AUTOSAR XML (schema 4-0-3)
package /CalibrationComponents
  parameter sw component type HMIR: data-type-mapping=HMIR_CodeDataTypeMappingsSet
    provide port HMIR_Pport: provided-interface=HMIR_if
      provided-com-specs:
        init-value=55, parameter=KeHMIR_Ah_BattRatedCap
        init-value=55, parameter=KeHMIR_Ah_CellCapacity
        init-value=18.299999237060547, parameter=KeHMIR_I_MaxChargeCur
        init-value=97, parameter=KeHMIR_Pct_PackSocDashHundred
        init-value=3, parameter=KeHMIR_Pct_PackSocDashZero
        init-value=350.3999938964844, parameter=KeHMIR_U_BattRatedVoltageValue
        init-value=2.799999952316284, parameter=KeHMIR_U_CellDischCutVoltage
        init-value=403.20001220703125, parameter=KeHMIR_U_MaxChargeVol
        init-value=268.79998779296875, parameter=KeHMIR_U_MinChargeVol
        init-value=19.299999237060547, parameter=KeHMIR_kE_BattRatedEnergyValue
        init-value=250, parameter=KeHMIR_kl_ElectricRangeDTE_Value
        init-value=100, parameter=KeHMIR_kl_TotalDrivenBatOvrdVal
        init-value=110105, parameter=KeHMIR_k_PRTVer
        init-value=0, parameter=KeHMIR_b_TotalDrivenBatOvrd
        init-value=6, parameter=KeHMIR_k_BattManucCodeVal
        init-value=1, parameter=KeHMIR_k_BattNum
        init-value=1, parameter=KeHMIR_k_BattPackParallel
        init-value=96, parameter=KeHMIR_k_BattPackSerial
        init-value=1, parameter=KeHMIR_k_BattSum
        init-value=4, parameter=KeHMIR_k_BattTypeValue
        init-value=96, parameter=KeHMIR_k_CellNum
        init-value=10, parameter=KeHMIR_k_CodeL
        init-value=29, parameter=KeHMIR_k_FaultSum
        init-value=2, parameter=KeHMIR_k_HWVer
        init-value=96, parameter=KeHMIR_k_MaxCellIndex
        init-value=1, parameter=KeHMIR_k_MaxTNumPack
        init-value=16, parameter=KeHMIR_k_MaxTempIndex
        init-value=1, parameter=KeHMIR_k_MaxVNumPack
        init-value=1, parameter=KeHMIR_k_MinCellIndex
        init-value=1, parameter=KeHMIR_k_MinTNumPack
        init-value=1, parameter=KeHMIR_k_MinTempIndex
        init-value=1, parameter=KeHMIR_k_MinVNumPack
        init-value=16, parameter=KeHMIR_k_TempNum
package /HMIR_Code_pkg/HMIR_Code_swc
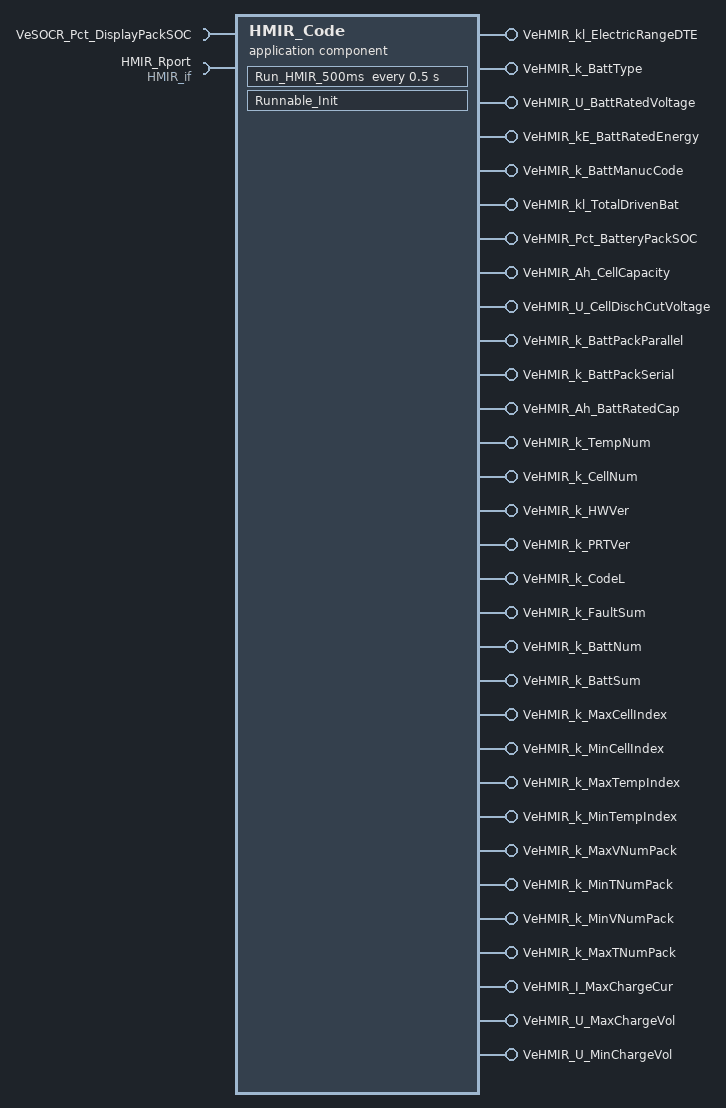
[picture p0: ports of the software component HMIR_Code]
  application sw component type HMIR_Code
    require port VeSOCR_Pct_DisplayPackSOC: nonqueued-receiver-com-spec{data-element=VeSOCR_Pct_DisplayPackSOC, init-value=0}, required-interface=VeSOCR_Pct_DisplayPackSOC
    31 x provide port:
      VeHMIR_kl_ElectricRangeDTE: nonqueued-sender-com-spec{data-element=VeHMIR_kl_ElectricRangeDTE, init-value=0}, provided-interface=VeHMIR_kl_ElectricRangeDTE
      VeHMIR_k_BattType: nonqueued-sender-com-spec{data-element=VeHMIR_k_BattType, init-value=0}, provided-interface=VeHMIR_k_BattType
      VeHMIR_U_BattRatedVoltage: nonqueued-sender-com-spec{data-element=VeHMIR_U_BattRatedVoltage, init-value=0}, provided-interface=VeHMIR_U_BattRatedVoltage
      VeHMIR_kE_BattRatedEnergy: nonqueued-sender-com-spec{data-element=VeHMIR_kE_BattRatedEnergy, init-value=0}, provided-interface=VeHMIR_kE_BattRatedEnergy
      VeHMIR_k_BattManucCode: nonqueued-sender-com-spec{data-element=VeHMIR_k_BattManucCode, init-value=0}, provided-interface=VeHMIR_k_BattManucCode
      VeHMIR_kl_TotalDrivenBat: nonqueued-sender-com-spec{data-element=VeHMIR_kl_TotalDrivenBat, init-value=0}, provided-interface=VeHMIR_kl_TotalDrivenBat
      VeHMIR_Pct_BatteryPackSOC: nonqueued-sender-com-spec{data-element=VeHMIR_Pct_BatteryPackSOC, init-value=0}, provided-interface=VeHMIR_Pct_BatteryPackSOC
      VeHMIR_Ah_CellCapacity: nonqueued-sender-com-spec{data-element=VeHMIR_Ah_CellCapacity, init-value=0}, provided-interface=VeHMIR_Ah_CellCapacity
      VeHMIR_U_CellDischCutVoltage: nonqueued-sender-com-spec{data-element=VeHMIR_U_CellDischCutVoltage, init-value=0}, provided-interface=VeHMIR_U_CellDischCutVoltage
      VeHMIR_k_BattPackParallel: nonqueued-sender-com-spec{data-element=VeHMIR_k_BattPackParallel, init-value=0}, provided-interface=VeHMIR_k_BattPackParallel
      VeHMIR_k_BattPackSerial: nonqueued-sender-com-spec{data-element=VeHMIR_k_BattPackSerial, init-value=0}, provided-interface=VeHMIR_k_BattPackSerial
      VeHMIR_Ah_BattRatedCap: nonqueued-sender-com-spec{data-element=VeHMIR_Ah_BattRatedCap, init-value=0}, provided-interface=VeHMIR_Ah_BattRatedCap
      VeHMIR_k_TempNum: nonqueued-sender-com-spec{data-element=VeHMIR_k_TempNum, init-value=0}, provided-interface=VeHMIR_k_TempNum
      VeHMIR_k_CellNum: nonqueued-sender-com-spec{data-element=VeHMIR_k_CellNum, init-value=0}, provided-interface=VeHMIR_k_CellNum
      VeHMIR_k_HWVer: nonqueued-sender-com-spec{data-element=VeHMIR_k_HWVer, init-value=0}, provided-interface=VeHMIR_k_HWVer
      VeHMIR_k_PRTVer: nonqueued-sender-com-spec{data-element=VeHMIR_k_PRTVer, init-value=0}, provided-interface=VeHMIR_k_PRTVer
      VeHMIR_k_CodeL: nonqueued-sender-com-spec{data-element=VeHMIR_k_CodeL, init-value=0}, provided-interface=VeHMIR_k_CodeL
      VeHMIR_k_FaultSum: nonqueued-sender-com-spec{data-element=VeHMIR_k_FaultSum, init-value=0}, provided-interface=VeHMIR_k_FaultSum
      VeHMIR_k_BattNum: nonqueued-sender-com-spec{data-element=VeHMIR_k_BattNum, init-value=0}, provided-interface=VeHMIR_k_BattNum
      VeHMIR_k_BattSum: nonqueued-sender-com-spec{data-element=VeHMIR_k_BattSum, init-value=0}, provided-interface=VeHMIR_k_BattSum
      VeHMIR_k_MaxCellIndex: nonqueued-sender-com-spec{data-element=VeHMIR_k_MaxCellIndex, init-value=0}, provided-interface=VeHMIR_k_MaxCellIndex
      VeHMIR_k_MinCellIndex: nonqueued-sender-com-spec{data-element=VeHMIR_k_MinCellIndex, init-value=0}, provided-interface=VeHMIR_k_MinCellIndex
      VeHMIR_k_MaxTempIndex: nonqueued-sender-com-spec{data-element=VeHMIR_k_MaxTempIndex, init-value=0}, provided-interface=VeHMIR_k_MaxTempIndex
      VeHMIR_k_MinTempIndex: nonqueued-sender-com-spec{data-element=VeHMIR_k_MinTempIndex, init-value=0}, provided-interface=VeHMIR_k_MinTempIndex
      VeHMIR_k_MaxVNumPack: nonqueued-sender-com-spec{data-element=VeHMIR_k_MaxVNumPack, init-value=0}, provided-interface=VeHMIR_k_MaxVNumPack
      VeHMIR_k_MinTNumPack: nonqueued-sender-com-spec{data-element=VeHMIR_k_MinTNumPack, init-value=0}, provided-interface=VeHMIR_k_MinTNumPack
      VeHMIR_k_MinVNumPack: nonqueued-sender-com-spec{data-element=VeHMIR_k_MinVNumPack, init-value=0}, provided-interface=VeHMIR_k_MinVNumPack
      VeHMIR_k_MaxTNumPack: nonqueued-sender-com-spec{data-element=VeHMIR_k_MaxTNumPack, init-value=0}, provided-interface=VeHMIR_k_MaxTNumPack
      VeHMIR_I_MaxChargeCur: nonqueued-sender-com-spec{data-element=VeHMIR_I_MaxChargeCur, init-value=0}, provided-interface=VeHMIR_I_MaxChargeCur
      VeHMIR_U_MaxChargeVol: nonqueued-sender-com-spec{data-element=VeHMIR_U_MaxChargeVol, init-value=0}, provided-interface=VeHMIR_U_MaxChargeVol
      VeHMIR_U_MinChargeVol: nonqueued-sender-com-spec{data-element=VeHMIR_U_MinChargeVol, init-value=0}, provided-interface=VeHMIR_U_MinChargeVol
    require port HMIR_Rport: required-interface=HMIR_if
    behavior HMIR_Code: constant-value-mapping=HMIR_Code_datatype_AVS_MappingSet, data-type-mapping=HMIR_CodeDataTypeMappingsSet, handle-termination-and-restart=NO-SUPPORT
      timing event Event_Run_HMIR_500ms: start-on-event=Run_HMIR_500ms, period=0.5
      runnable Runnable_Init: symbol=HMIR_Code_Init
        data-send-points:
          29 x access:
            OUT_VeHMIR_kl_ElectricRangeDTE_VeHMIR_kl_ElectricRangeDTE: accessed-variable=VeHMIR_kl_ElectricRangeDTE.VeHMIR_kl_ElectricRangeDTE
            OUT_VeHMIR_k_BattType_VeHMIR_k_BattType: accessed-variable=VeHMIR_k_BattType.VeHMIR_k_BattType
            OUT_VeHMIR_U_BattRatedVoltage_VeHMIR_U_BattRatedVoltage: accessed-variable=VeHMIR_U_BattRatedVoltage.VeHMIR_U_BattRatedVoltage
            OUT_VeHMIR_kE_BattRatedEnergy_VeHMIR_kE_BattRatedEnergy: accessed-variable=VeHMIR_kE_BattRatedEnergy.VeHMIR_kE_BattRatedEnergy
            OUT_VeHMIR_k_BattManucCode_VeHMIR_k_BattManucCode: accessed-variable=VeHMIR_k_BattManucCode.VeHMIR_k_BattManucCode
            OUT_VeHMIR_Ah_CellCapacity_VeHMIR_Ah_CellCapacity: accessed-variable=VeHMIR_Ah_CellCapacity.VeHMIR_Ah_CellCapacity
            OUT_VeHMIR_U_CellDischCutVoltage_VeHMIR_U_CellDischCutVoltage: accessed-variable=VeHMIR_U_CellDischCutVoltage.VeHMIR_U_CellDischCutVoltage
            OUT_VeHMIR_k_BattPackParallel_VeHMIR_k_BattPackParallel: accessed-variable=VeHMIR_k_BattPackParallel.VeHMIR_k_BattPackParallel
            OUT_VeHMIR_k_BattPackSerial_VeHMIR_k_BattPackSerial: accessed-variable=VeHMIR_k_BattPackSerial.VeHMIR_k_BattPackSerial
            OUT_VeHMIR_Ah_BattRatedCap_VeHMIR_Ah_BattRatedCap: accessed-variable=VeHMIR_Ah_BattRatedCap.VeHMIR_Ah_BattRatedCap
            OUT_VeHMIR_k_TempNum_VeHMIR_k_TempNum: accessed-variable=VeHMIR_k_TempNum.VeHMIR_k_TempNum
            OUT_VeHMIR_k_CellNum_VeHMIR_k_CellNum: accessed-variable=VeHMIR_k_CellNum.VeHMIR_k_CellNum
            OUT_VeHMIR_k_HWVer_VeHMIR_k_HWVer: accessed-variable=VeHMIR_k_HWVer.VeHMIR_k_HWVer
            OUT_VeHMIR_k_PRTVer_VeHMIR_k_PRTVer: accessed-variable=VeHMIR_k_PRTVer.VeHMIR_k_PRTVer
            OUT_VeHMIR_k_CodeL_VeHMIR_k_CodeL: accessed-variable=VeHMIR_k_CodeL.VeHMIR_k_CodeL
            OUT_VeHMIR_k_FaultSum_VeHMIR_k_FaultSum: accessed-variable=VeHMIR_k_FaultSum.VeHMIR_k_FaultSum
            OUT_VeHMIR_k_BattNum_VeHMIR_k_BattNum: accessed-variable=VeHMIR_k_BattNum.VeHMIR_k_BattNum
            OUT_VeHMIR_k_BattSum_VeHMIR_k_BattSum: accessed-variable=VeHMIR_k_BattSum.VeHMIR_k_BattSum
            OUT_VeHMIR_k_MaxCellIndex_VeHMIR_k_MaxCellIndex: accessed-variable=VeHMIR_k_MaxCellIndex.VeHMIR_k_MaxCellIndex
            OUT_VeHMIR_k_MinCellIndex_VeHMIR_k_MinCellIndex: accessed-variable=VeHMIR_k_MinCellIndex.VeHMIR_k_MinCellIndex
            OUT_VeHMIR_k_MaxTempIndex_VeHMIR_k_MaxTempIndex: accessed-variable=VeHMIR_k_MaxTempIndex.VeHMIR_k_MaxTempIndex
            OUT_VeHMIR_k_MinTempIndex_VeHMIR_k_MinTempIndex: accessed-variable=VeHMIR_k_MinTempIndex.VeHMIR_k_MinTempIndex
            OUT_VeHMIR_k_MaxVNumPack_VeHMIR_k_MaxVNumPack: accessed-variable=VeHMIR_k_MaxVNumPack.VeHMIR_k_MaxVNumPack
            OUT_VeHMIR_k_MinTNumPack_VeHMIR_k_MinTNumPack: accessed-variable=VeHMIR_k_MinTNumPack.VeHMIR_k_MinTNumPack
            OUT_VeHMIR_k_MinVNumPack_VeHMIR_k_MinVNumPack: accessed-variable=VeHMIR_k_MinVNumPack.VeHMIR_k_MinVNumPack
            OUT_VeHMIR_k_MaxTNumPack_VeHMIR_k_MaxTNumPack: accessed-variable=VeHMIR_k_MaxTNumPack.VeHMIR_k_MaxTNumPack
            OUT_VeHMIR_I_MaxChargeCur_VeHMIR_I_MaxChargeCur: accessed-variable=VeHMIR_I_MaxChargeCur.VeHMIR_I_MaxChargeCur
            OUT_VeHMIR_U_MaxChargeVol_VeHMIR_U_MaxChargeVol: accessed-variable=VeHMIR_U_MaxChargeVol.VeHMIR_U_MaxChargeVol
            OUT_VeHMIR_U_MinChargeVol_VeHMIR_U_MinChargeVol: accessed-variable=VeHMIR_U_MinChargeVol.VeHMIR_U_MinChargeVol
        29 x parameter access:
          CALPRM_HMIR_Rport_KeHMIR_Ah_BattRatedCap: accessed-parameter=HMIR_Rport.KeHMIR_Ah_BattRatedCap
          CALPRM_HMIR_Rport_KeHMIR_Ah_CellCapacity: accessed-parameter=HMIR_Rport.KeHMIR_Ah_CellCapacity
          CALPRM_HMIR_Rport_KeHMIR_I_MaxChargeCur: accessed-parameter=HMIR_Rport.KeHMIR_I_MaxChargeCur
          CALPRM_HMIR_Rport_KeHMIR_U_BattRatedVoltageValue: accessed-parameter=HMIR_Rport.KeHMIR_U_BattRatedVoltageValue
          CALPRM_HMIR_Rport_KeHMIR_U_CellDischCutVoltage: accessed-parameter=HMIR_Rport.KeHMIR_U_CellDischCutVoltage
          CALPRM_HMIR_Rport_KeHMIR_U_MaxChargeVol: accessed-parameter=HMIR_Rport.KeHMIR_U_MaxChargeVol
          CALPRM_HMIR_Rport_KeHMIR_U_MinChargeVol: accessed-parameter=HMIR_Rport.KeHMIR_U_MinChargeVol
          CALPRM_HMIR_Rport_KeHMIR_kE_BattRatedEnergyValue: accessed-parameter=HMIR_Rport.KeHMIR_kE_BattRatedEnergyValue
          CALPRM_HMIR_Rport_KeHMIR_k_BattManucCodeVal: accessed-parameter=HMIR_Rport.KeHMIR_k_BattManucCodeVal
          CALPRM_HMIR_Rport_KeHMIR_k_BattNum: accessed-parameter=HMIR_Rport.KeHMIR_k_BattNum
          CALPRM_HMIR_Rport_KeHMIR_k_BattPackParallel: accessed-parameter=HMIR_Rport.KeHMIR_k_BattPackParallel
          CALPRM_HMIR_Rport_KeHMIR_k_BattPackSerial: accessed-parameter=HMIR_Rport.KeHMIR_k_BattPackSerial
          CALPRM_HMIR_Rport_KeHMIR_k_BattSum: accessed-parameter=HMIR_Rport.KeHMIR_k_BattSum
          CALPRM_HMIR_Rport_KeHMIR_k_BattTypeValue: accessed-parameter=HMIR_Rport.KeHMIR_k_BattTypeValue
          CALPRM_HMIR_Rport_KeHMIR_k_CellNum: accessed-parameter=HMIR_Rport.KeHMIR_k_CellNum
          CALPRM_HMIR_Rport_KeHMIR_k_CodeL: accessed-parameter=HMIR_Rport.KeHMIR_k_CodeL
          CALPRM_HMIR_Rport_KeHMIR_k_FaultSum: accessed-parameter=HMIR_Rport.KeHMIR_k_FaultSum
          CALPRM_HMIR_Rport_KeHMIR_k_HWVer: accessed-parameter=HMIR_Rport.KeHMIR_k_HWVer
          CALPRM_HMIR_Rport_KeHMIR_k_MaxCellIndex: accessed-parameter=HMIR_Rport.KeHMIR_k_MaxCellIndex
          CALPRM_HMIR_Rport_KeHMIR_k_MaxTNumPack: accessed-parameter=HMIR_Rport.KeHMIR_k_MaxTNumPack
          CALPRM_HMIR_Rport_KeHMIR_k_MaxTempIndex: accessed-parameter=HMIR_Rport.KeHMIR_k_MaxTempIndex
          CALPRM_HMIR_Rport_KeHMIR_k_MaxVNumPack: accessed-parameter=HMIR_Rport.KeHMIR_k_MaxVNumPack
          CALPRM_HMIR_Rport_KeHMIR_k_MinCellIndex: accessed-parameter=HMIR_Rport.KeHMIR_k_MinCellIndex
          CALPRM_HMIR_Rport_KeHMIR_k_MinTNumPack: accessed-parameter=HMIR_Rport.KeHMIR_k_MinTNumPack
          CALPRM_HMIR_Rport_KeHMIR_k_MinTempIndex: accessed-parameter=HMIR_Rport.KeHMIR_k_MinTempIndex
          CALPRM_HMIR_Rport_KeHMIR_k_MinVNumPack: accessed-parameter=HMIR_Rport.KeHMIR_k_MinVNumPack
          CALPRM_HMIR_Rport_KeHMIR_k_PRTVer: accessed-parameter=HMIR_Rport.KeHMIR_k_PRTVer
          CALPRM_HMIR_Rport_KeHMIR_k_TempNum: accessed-parameter=HMIR_Rport.KeHMIR_k_TempNum
          CALPRM_HMIR_Rport_KeHMIR_kl_ElectricRangeDTE_Value: accessed-parameter=HMIR_Rport.KeHMIR_kl_ElectricRangeDTE_Value
      runnable Run_HMIR_500ms
        data-read-access:
          access IN_VeSOCR_Pct_DisplayPackSOC_VeSOCR_Pct_DisplayPackSOC: accessed-variable=VeSOCR_Pct_DisplayPackSOC.VeSOCR_Pct_DisplayPackSOC
        data-send-points:
          31 x access:
            OUT_VeHMIR_kl_ElectricRangeDTE_VeHMIR_kl_ElectricRangeDTE: accessed-variable=VeHMIR_kl_ElectricRangeDTE.VeHMIR_kl_ElectricRangeDTE
            OUT_VeHMIR_k_BattType_VeHMIR_k_BattType: accessed-variable=VeHMIR_k_BattType.VeHMIR_k_BattType
            OUT_VeHMIR_U_BattRatedVoltage_VeHMIR_U_BattRatedVoltage: accessed-variable=VeHMIR_U_BattRatedVoltage.VeHMIR_U_BattRatedVoltage
            OUT_VeHMIR_kE_BattRatedEnergy_VeHMIR_kE_BattRatedEnergy: accessed-variable=VeHMIR_kE_BattRatedEnergy.VeHMIR_kE_BattRatedEnergy
            OUT_VeHMIR_k_BattManucCode_VeHMIR_k_BattManucCode: accessed-variable=VeHMIR_k_BattManucCode.VeHMIR_k_BattManucCode
            OUT_VeHMIR_kl_TotalDrivenBat_VeHMIR_kl_TotalDrivenBat: accessed-variable=VeHMIR_kl_TotalDrivenBat.VeHMIR_kl_TotalDrivenBat
            OUT_VeHMIR_Pct_BatteryPackSOC_VeHMIR_Pct_BatteryPackSOC: accessed-variable=VeHMIR_Pct_BatteryPackSOC.VeHMIR_Pct_BatteryPackSOC
            OUT_VeHMIR_Ah_CellCapacity_VeHMIR_Ah_CellCapacity: accessed-variable=VeHMIR_Ah_CellCapacity.VeHMIR_Ah_CellCapacity
            OUT_VeHMIR_U_CellDischCutVoltage_VeHMIR_U_CellDischCutVoltage: accessed-variable=VeHMIR_U_CellDischCutVoltage.VeHMIR_U_CellDischCutVoltage
            OUT_VeHMIR_k_BattPackParallel_VeHMIR_k_BattPackParallel: accessed-variable=VeHMIR_k_BattPackParallel.VeHMIR_k_BattPackParallel
            OUT_VeHMIR_k_BattPackSerial_VeHMIR_k_BattPackSerial: accessed-variable=VeHMIR_k_BattPackSerial.VeHMIR_k_BattPackSerial
            OUT_VeHMIR_Ah_BattRatedCap_VeHMIR_Ah_BattRatedCap: accessed-variable=VeHMIR_Ah_BattRatedCap.VeHMIR_Ah_BattRatedCap
            OUT_VeHMIR_k_TempNum_VeHMIR_k_TempNum: accessed-variable=VeHMIR_k_TempNum.VeHMIR_k_TempNum
            OUT_VeHMIR_k_CellNum_VeHMIR_k_CellNum: accessed-variable=VeHMIR_k_CellNum.VeHMIR_k_CellNum
            OUT_VeHMIR_k_HWVer_VeHMIR_k_HWVer: accessed-variable=VeHMIR_k_HWVer.VeHMIR_k_HWVer
            OUT_VeHMIR_k_PRTVer_VeHMIR_k_PRTVer: accessed-variable=VeHMIR_k_PRTVer.VeHMIR_k_PRTVer
            OUT_VeHMIR_k_CodeL_VeHMIR_k_CodeL: accessed-variable=VeHMIR_k_CodeL.VeHMIR_k_CodeL
            OUT_VeHMIR_k_FaultSum_VeHMIR_k_FaultSum: accessed-variable=VeHMIR_k_FaultSum.VeHMIR_k_FaultSum
            OUT_VeHMIR_k_BattNum_VeHMIR_k_BattNum: accessed-variable=VeHMIR_k_BattNum.VeHMIR_k_BattNum
            OUT_VeHMIR_k_BattSum_VeHMIR_k_BattSum: accessed-variable=VeHMIR_k_BattSum.VeHMIR_k_BattSum
            OUT_VeHMIR_k_MaxCellIndex_VeHMIR_k_MaxCellIndex: accessed-variable=VeHMIR_k_MaxCellIndex.VeHMIR_k_MaxCellIndex
            OUT_VeHMIR_k_MinCellIndex_VeHMIR_k_MinCellIndex: accessed-variable=VeHMIR_k_MinCellIndex.VeHMIR_k_MinCellIndex
            OUT_VeHMIR_k_MaxTempIndex_VeHMIR_k_MaxTempIndex: accessed-variable=VeHMIR_k_MaxTempIndex.VeHMIR_k_MaxTempIndex
            OUT_VeHMIR_k_MinTempIndex_VeHMIR_k_MinTempIndex: accessed-variable=VeHMIR_k_MinTempIndex.VeHMIR_k_MinTempIndex
            OUT_VeHMIR_k_MaxVNumPack_VeHMIR_k_MaxVNumPack: accessed-variable=VeHMIR_k_MaxVNumPack.VeHMIR_k_MaxVNumPack
            OUT_VeHMIR_k_MinTNumPack_VeHMIR_k_MinTNumPack: accessed-variable=VeHMIR_k_MinTNumPack.VeHMIR_k_MinTNumPack
            OUT_VeHMIR_k_MinVNumPack_VeHMIR_k_MinVNumPack: accessed-variable=VeHMIR_k_MinVNumPack.VeHMIR_k_MinVNumPack
            OUT_VeHMIR_k_MaxTNumPack_VeHMIR_k_MaxTNumPack: accessed-variable=VeHMIR_k_MaxTNumPack.VeHMIR_k_MaxTNumPack
            OUT_VeHMIR_I_MaxChargeCur_VeHMIR_I_MaxChargeCur: accessed-variable=VeHMIR_I_MaxChargeCur.VeHMIR_I_MaxChargeCur
            OUT_VeHMIR_U_MaxChargeVol_VeHMIR_U_MaxChargeVol: accessed-variable=VeHMIR_U_MaxChargeVol.VeHMIR_U_MaxChargeVol
            OUT_VeHMIR_U_MinChargeVol_VeHMIR_U_MinChargeVol: accessed-variable=VeHMIR_U_MinChargeVol.VeHMIR_U_MinChargeVol
        35 x parameter access:
          CALPRM_HMIR_Rport_KeHMIR_Ah_BattRatedCap: accessed-parameter=HMIR_Rport.KeHMIR_Ah_BattRatedCap
          CALPRM_HMIR_Rport_KeHMIR_Ah_CellCapacity: accessed-parameter=HMIR_Rport.KeHMIR_Ah_CellCapacity
          CALPRM_HMIR_Rport_KeHMIR_I_MaxChargeCur: accessed-parameter=HMIR_Rport.KeHMIR_I_MaxChargeCur
          CALPRM_HMIR_Rport_KeHMIR_Pct_PackSocDashHundred: accessed-parameter=HMIR_Rport.KeHMIR_Pct_PackSocDashHundred
          CALPRM_HMIR_Rport_KeHMIR_Pct_PackSocDashZero: accessed-parameter=HMIR_Rport.KeHMIR_Pct_PackSocDashZero
          CALPRM_HMIR_Rport_KeHMIR_U_BattRatedVoltageValue: accessed-parameter=HMIR_Rport.KeHMIR_U_BattRatedVoltageValue
          CALPRM_HMIR_Rport_KeHMIR_U_CellDischCutVoltage: accessed-parameter=HMIR_Rport.KeHMIR_U_CellDischCutVoltage
          CALPRM_HMIR_Rport_KeHMIR_U_MaxChargeVol: accessed-parameter=HMIR_Rport.KeHMIR_U_MaxChargeVol
          CALPRM_HMIR_Rport_KeHMIR_U_MinChargeVol: accessed-parameter=HMIR_Rport.KeHMIR_U_MinChargeVol
          CALPRM_HMIR_Rport_KeHMIR_b_TotalDrivenBatOvrd: accessed-parameter=HMIR_Rport.KeHMIR_b_TotalDrivenBatOvrd
          CALPRM_HMIR_Rport_KeHMIR_kE_BattRatedEnergyValue: accessed-parameter=HMIR_Rport.KeHMIR_kE_BattRatedEnergyValue
          CALPRM_HMIR_Rport_KeHMIR_k_BattManucCodeVal: accessed-parameter=HMIR_Rport.KeHMIR_k_BattManucCodeVal
          CALPRM_HMIR_Rport_KeHMIR_k_BattNum: accessed-parameter=HMIR_Rport.KeHMIR_k_BattNum
          CALPRM_HMIR_Rport_KeHMIR_k_BattPackParallel: accessed-parameter=HMIR_Rport.KeHMIR_k_BattPackParallel
          CALPRM_HMIR_Rport_KeHMIR_k_BattPackSerial: accessed-parameter=HMIR_Rport.KeHMIR_k_BattPackSerial
          CALPRM_HMIR_Rport_KeHMIR_k_BattSum: accessed-parameter=HMIR_Rport.KeHMIR_k_BattSum
          CALPRM_HMIR_Rport_KeHMIR_k_BattTypeValue: accessed-parameter=HMIR_Rport.KeHMIR_k_BattTypeValue
          CALPRM_HMIR_Rport_KeHMIR_k_CellNum: accessed-parameter=HMIR_Rport.KeHMIR_k_CellNum
          CALPRM_HMIR_Rport_KeHMIR_k_CodeL: accessed-parameter=HMIR_Rport.KeHMIR_k_CodeL
          CALPRM_HMIR_Rport_KeHMIR_k_FaultSum: accessed-parameter=HMIR_Rport.KeHMIR_k_FaultSum
          CALPRM_HMIR_Rport_KeHMIR_k_HWVer: accessed-parameter=HMIR_Rport.KeHMIR_k_HWVer
          CALPRM_HMIR_Rport_KeHMIR_k_MaxCellIndex: accessed-parameter=HMIR_Rport.KeHMIR_k_MaxCellIndex
          CALPRM_HMIR_Rport_KeHMIR_k_MaxTNumPack: accessed-parameter=HMIR_Rport.KeHMIR_k_MaxTNumPack
          CALPRM_HMIR_Rport_KeHMIR_k_MaxTempIndex: accessed-parameter=HMIR_Rport.KeHMIR_k_MaxTempIndex
          CALPRM_HMIR_Rport_KeHMIR_k_MaxVNumPack: accessed-parameter=HMIR_Rport.KeHMIR_k_MaxVNumPack
          CALPRM_HMIR_Rport_KeHMIR_k_MinCellIndex: accessed-parameter=HMIR_Rport.KeHMIR_k_MinCellIndex
          CALPRM_HMIR_Rport_KeHMIR_k_MinTNumPack: accessed-parameter=HMIR_Rport.KeHMIR_k_MinTNumPack
          CALPRM_HMIR_Rport_KeHMIR_k_MinTempIndex: accessed-parameter=HMIR_Rport.KeHMIR_k_MinTempIndex
          CALPRM_HMIR_Rport_KeHMIR_k_MinVNumPack: accessed-parameter=HMIR_Rport.KeHMIR_k_MinVNumPack
          CALPRM_HMIR_Rport_KeHMIR_k_PRTVer: accessed-parameter=HMIR_Rport.KeHMIR_k_PRTVer
          CALPRM_HMIR_Rport_KeHMIR_k_TempNum: accessed-parameter=HMIR_Rport.KeHMIR_k_TempNum
          CALPRM_HMIR_Rport_KeHMIR_kl_ElectricRangeDTE_Value: accessed-parameter=HMIR_Rport.KeHMIR_kl_ElectricRangeDTE_Value
          CALPRM_HMIR_Rport_KeHMIR_kl_TotalDrivenBatOvrdVal: accessed-parameter=HMIR_Rport.KeHMIR_kl_TotalDrivenBatOvrdVal
          SCALPRM_KtHMIR_kl_SOC2: accessed-parameter=KtHMIR_kl_SOC2, sw-calprm-axis-set=sw-axis-individual=sw-variable=VeSOCR_Pct_DisplayPackSOC.VeSOCR_Pct_DisplayPackSOC
          SCALPRM_KtHMIR_kl_SOC2Range: accessed-parameter=KtHMIR_kl_SOC2Range, sw-calprm-axis-set={sw-axis-index=1, sw-axis-grouped=ar-parameter=KtHMIR_kl_SOC2}
      shared-parameters:
        parameter data prototype KtHMIR_kl_SOC2: category=COM_AXIS, sw-calibration-access=READ-WRITE, type=Appl_KtHMIR_kl_SOC2, init-value=constant-reference={short-label=KtHMIR_kl_SOC2, constant=KtHMIR_kl_SOC2}
        parameter data prototype KtHMIR_kl_SOC2Range: category=CURVE, sw-calibration-access=READ-WRITE, type=Appl_KtHMIR_kl_SOC2Range, init-value=constant-reference={short-label=KtHMIR_kl_SOC2Range, constant=KtHMIR_kl_SOC2Range}
